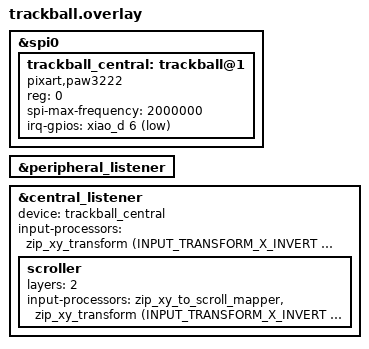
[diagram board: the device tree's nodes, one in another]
&spi0 {
    status = "okay";

    trackball_central: trackball@1 {
        status = "okay";
        compatible = "pixart,paw3222";
        reg = <0>;
        spi-max-frequency = <2000000>;
        irq-gpios = <&xiao_d 6 (GPIO_ACTIVE_LOW | GPIO_PULL_UP)>;
    };
};

&peripheral_listener {
    status = "okay";
};

&central_listener {
    status = "okay";
    device = <&trackball_central>;

    /* ===== ポインタ =====
     * センサ座標が逆なので X/Y 両方反転
     */
    input-processors =
        <&zip_xy_transform (INPUT_TRANSFORM_X_INVERT | INPUT_TRANSFORM_Y_INVERT)>;

    /* ===== スクロール（layer 2 のみ） ===== */
    scroller {
        layers = <2>;

        input-processors =
            <&zip_xy_to_scroll_mapper>,
            /* mapper が反転した X を元に戻し、Y だけ反転 */
            <&zip_xy_transform (INPUT_TRANSFORM_X_INVERT | INPUT_TRANSFORM_Y_INVERT)>;
    };
};
